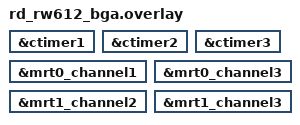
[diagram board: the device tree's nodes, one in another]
/*
 * Copyright 2023 NXP
 *
 * SPDX-License-Identifier: Apache-2.0
 */

&ctimer1 {
	status = "okay";
};

&ctimer2 {
	status = "okay";
};

&ctimer3 {
	status = "okay";
};

&mrt0_channel1 {
	status = "okay";
};

&mrt0_channel3 {
	status = "okay";
};

&mrt1_channel2 {
	status = "okay";
};

&mrt1_channel3 {
	status = "okay";
};
